AUTOSAR XML (schema 3.1.2)
package /Components/SWC_FISA
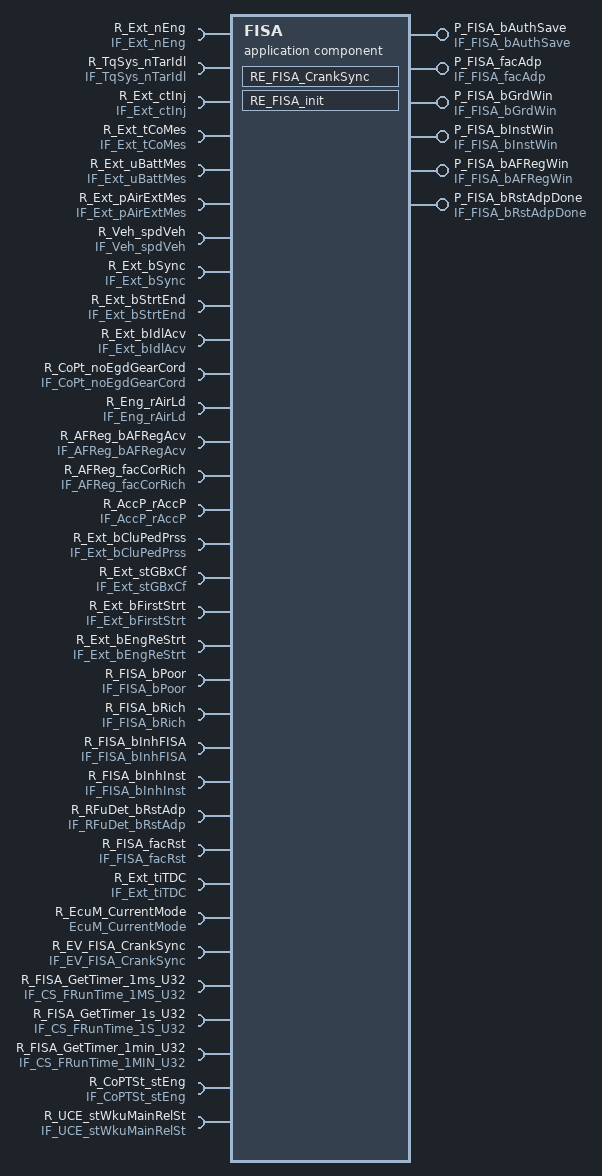
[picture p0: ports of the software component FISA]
  application software component type FISA
    6 x provide port:
      P_FISA_bAuthSave: unqueued-sender-com-spec{data-element=FISA_bAuthSave, can-invalidate=false, init-value=InitValue_Boolean_0}, provided-interface=IF_FISA_bAuthSave
      P_FISA_facAdp: unqueued-sender-com-spec{data-element=FISA_facAdp, can-invalidate=false, init-value=InitValue_UInt8_0}, provided-interface=IF_FISA_facAdp
      P_FISA_bGrdWin: unqueued-sender-com-spec{data-element=FISA_bGrdWin, can-invalidate=false, init-value=InitValue_Boolean_01}, provided-interface=IF_FISA_bGrdWin
      P_FISA_bInstWin: unqueued-sender-com-spec{data-element=FISA_bInstWin, can-invalidate=false, init-value=InitValue_Boolean_03}, provided-interface=IF_FISA_bInstWin
      P_FISA_bAFRegWin: unqueued-sender-com-spec{data-element=FISA_bAFRegWin, can-invalidate=false, init-value=InitValue_Boolean_05}, provided-interface=IF_FISA_bAFRegWin
      P_FISA_bRstAdpDone: unqueued-sender-com-spec{data-element=FISA_bRstAdpDone, can-invalidate=false, init-value=InitValue_Boolean_07}, provided-interface=IF_FISA_bRstAdpDone
    33 x require port:
      R_Ext_nEng: unqueued-receiver-com-spec{data-element=Ext_nEng, init-value=ConstantValue, resync-time=0}, required-interface=IF_Ext_nEng
      R_TqSys_nTarIdl: unqueued-receiver-com-spec{data-element=TqSys_nTarIdl, init-value=ConstantValue9, resync-time=0}, required-interface=IF_TqSys_nTarIdl
      R_Ext_ctInj: unqueued-receiver-com-spec{data-element=Ext_ctInj, init-value=InitValue_UInt16_0, resync-time=0}, required-interface=IF_Ext_ctInj
      R_Ext_tCoMes: unqueued-receiver-com-spec{data-element=Ext_tCoMes, init-value=ConstantValue11, resync-time=0}, required-interface=IF_Ext_tCoMes
      R_Ext_uBattMes: unqueued-receiver-com-spec{data-element=Ext_uBattMes, init-value=InitValue_SInt16_0, resync-time=0}, required-interface=IF_Ext_uBattMes
      R_Ext_pAirExtMes: unqueued-receiver-com-spec{data-element=Ext_pAirExtMes, init-value=ConstantValue13, resync-time=0}, required-interface=IF_Ext_pAirExtMes
      R_Veh_spdVeh: unqueued-receiver-com-spec{data-element=Veh_spdVeh, init-value=ConstantValue15, resync-time=0}, required-interface=IF_Veh_spdVeh
      R_Ext_bSync: unqueued-receiver-com-spec{data-element=Ext_bSync, init-value=InitValue_Boolean_017, resync-time=0}, required-interface=IF_Ext_bSync
      R_Ext_bStrtEnd: unqueued-receiver-com-spec{data-element=Ext_bStrtEnd, init-value=InitValue_Boolean_019, resync-time=0}, required-interface=IF_Ext_bStrtEnd
      R_Ext_bIdlAcv: unqueued-receiver-com-spec{data-element=Ext_bIdlAcv, init-value=InitValue_Boolean_021, resync-time=0}, required-interface=IF_Ext_bIdlAcv
      R_CoPt_noEgdGearCord: unqueued-receiver-com-spec{data-element=CoPt_noEgdGearCord, init-value=ConstantValue23, resync-time=0}, required-interface=IF_CoPt_noEgdGearCord
      R_Eng_rAirLd: unqueued-receiver-com-spec{data-element=Eng_rAirLd, init-value=InitValue_UInt16_025, resync-time=0}, required-interface=IF_Eng_rAirLd
      R_AFReg_bAFRegAcv: unqueued-receiver-com-spec{data-element=AFReg_bAFRegAcv, init-value=InitValue_Boolean_027, resync-time=0}, required-interface=IF_AFReg_bAFRegAcv
      R_AFReg_facCorRich: unqueued-receiver-com-spec{data-element=AFReg_facCorRich, init-value=InitValue_UInt16_029, resync-time=0}, required-interface=IF_AFReg_facCorRich
      R_AccP_rAccP: unqueued-receiver-com-spec{data-element=AccP_rAccP, init-value=ConstantValue31, resync-time=0}, required-interface=IF_AccP_rAccP
      R_Ext_bCluPedPrss: unqueued-receiver-com-spec{data-element=Ext_bCluPedPrss, init-value=ConstantValue33, resync-time=0}, required-interface=IF_Ext_bCluPedPrss
      R_Ext_stGBxCf: unqueued-receiver-com-spec{data-element=Ext_stGBxCf, init-value=ConstantValue35, resync-time=0}, required-interface=IF_Ext_stGBxCf
      R_Ext_bFirstStrt: unqueued-receiver-com-spec{data-element=Ext_bFirstStrt, init-value=InitValue_Boolean_037, resync-time=0}, required-interface=IF_Ext_bFirstStrt
      R_Ext_bEngReStrt: unqueued-receiver-com-spec{data-element=Ext_bEngReStrt, init-value=InitValue_Boolean_039, resync-time=0}, required-interface=IF_Ext_bEngReStrt
      R_FISA_bPoor: unqueued-receiver-com-spec{data-element=FISA_bPoor, init-value=InitValue_Boolean_041, resync-time=0}, required-interface=IF_FISA_bPoor
      R_FISA_bRich: unqueued-receiver-com-spec{data-element=FISA_bRich, init-value=InitValue_Boolean_043, resync-time=0}, required-interface=IF_FISA_bRich
      R_FISA_bInhFISA: unqueued-receiver-com-spec{data-element=FISA_bInhFISA, init-value=InitValue_Boolean_045, resync-time=0}, required-interface=IF_FISA_bInhFISA
      R_FISA_bInhInst: unqueued-receiver-com-spec{data-element=FISA_bInhInst, init-value=InitValue_Boolean_047, resync-time=0}, required-interface=IF_FISA_bInhInst
      R_RFuDet_bRstAdp: unqueued-receiver-com-spec{data-element=RFuDet_bRstAdp, init-value=InitValue_Boolean_049, resync-time=0}, required-interface=IF_RFuDet_bRstAdp
      R_FISA_facRst: unqueued-receiver-com-spec{data-element=FISA_facRst, init-value=InitValue_UInt8_051, resync-time=0}, required-interface=IF_FISA_facRst
      R_Ext_tiTDC: unqueued-receiver-com-spec{data-element=Ext_tiTDC, init-value=ConstantValue53, resync-time=0}, required-interface=IF_Ext_tiTDC
      R_EcuM_CurrentMode: required-interface=EcuM_CurrentMode
      R_EV_FISA_CrankSync: unqueued-receiver-com-spec{data-element=EV_FISA_CrankSync, init-value=InitValue_UInt8_055, resync-time=0}, required-interface=IF_EV_FISA_CrankSync
      R_FISA_GetTimer_1ms_U32: required-interface=IF_CS_FRunTime_1MS_U32
      R_FISA_GetTimer_1s_U32: required-interface=IF_CS_FRunTime_1S_U32
      R_FISA_GetTimer_1min_U32: required-interface=IF_CS_FRunTime_1MIN_U32
      R_CoPTSt_stEng: unqueued-receiver-com-spec{data-element=CoPTSt_stEng, init-value=ConstantValue57, resync-time=0}, required-interface=IF_CoPTSt_stEng
      R_UCE_stWkuMainRelSt: required-interface=IF_UCE_stWkuMainRelSt
  45 x constant specification:
    ConstantValue
      value:
        integer literal ConstantValue: type=DT_Ext_nEng, value=0
    ConstantValue11
      value:
        integer literal ConstantValue11: type=DT_Ext_tCoMes, value=20
    ConstantValue13
      value:
        integer literal ConstantValue13: type=DT_Ext_pAirExtMes, value=500
    ConstantValue15
      value:
        integer literal ConstantValue15: type=DT_Veh_spdVeh, value=0
    ConstantValue23
      value:
        integer literal ConstantValue23: type=DT_CoPt_noEgdGearCord, value=0
    ConstantValue31
      value:
        integer literal ConstantValue31: type=DT_AccP_rAccP, value=0
    ConstantValue33
      value:
        boolean literal ConstantValue33: type=DT_Ext_bCluPedPrss, value=false
    ConstantValue35
      value:
        integer literal ConstantValue35: type=DT_Ext_stGBxCf, value=0
    ConstantValue53
      value:
        integer literal ConstantValue53: type=DT_Ext_tiTDC, value=100
    ConstantValue57
      value:
        integer literal ConstantValue57: type=DT_CoPTSt_stEng, value=1
    ConstantValue9
      value:
        integer literal ConstantValue9: type=DT_TqSys_nTarIdl, value=0
    InitValue_Boolean_0
      value:
        boolean literal InitValue_Boolean_0: type=DT_FISA_bAuthSave, value=false
    InitValue_Boolean_01
      value:
        boolean literal InitValue_Boolean_01: type=DT_FISA_bGrdWin, value=false
    InitValue_Boolean_017
      value:
        boolean literal InitValue_Boolean_017: type=DT_Ext_bSync, value=false
    InitValue_Boolean_019
      value:
        boolean literal InitValue_Boolean_019: type=DT_Ext_bStrtEnd, value=false
    InitValue_Boolean_021
      value:
        boolean literal InitValue_Boolean_021: type=DT_Ext_bIdlAcv, value=false
    InitValue_Boolean_027
      value:
        boolean literal InitValue_Boolean_027: type=DT_AFReg_bAFRegAcv, value=false
    InitValue_Boolean_03
      value:
        boolean literal InitValue_Boolean_03: type=DT_FISA_bInstWin, value=false
    InitValue_Boolean_037
      value:
        boolean literal InitValue_Boolean_037: type=DT_Ext_bFirstStrt, value=false
    InitValue_Boolean_039
      value:
        boolean literal InitValue_Boolean_039: type=DT_Ext_bEngReStrt, value=false
    InitValue_Boolean_041
      value:
        boolean literal InitValue_Boolean_041: type=DT_FISA_bPoor, value=false
    InitValue_Boolean_043
      value:
        boolean literal InitValue_Boolean_043: type=DT_FISA_bRich, value=false
    InitValue_Boolean_045
      value:
        boolean literal InitValue_Boolean_045: type=DT_FISA_bInhFISA, value=false
    InitValue_Boolean_047
      value:
        boolean literal InitValue_Boolean_047: type=DT_FISA_bInhInst, value=false
    InitValue_Boolean_049
      value:
        boolean literal InitValue_Boolean_049: type=DT_RFuDet_bRstAdp, value=false
    InitValue_Boolean_05
      value:
        boolean literal InitValue_Boolean_05: type=DT_FISA_bAFRegWin, value=false
    InitValue_Boolean_061
      value:
        boolean literal InitValue_Boolean_061: type=DT_bAFRegWin, value=false
    InitValue_Boolean_065
      value:
        boolean literal InitValue_Boolean_065: type=DT_bAuthClc, value=false
    InitValue_Boolean_069
      value:
        boolean literal InitValue_Boolean_069: type=DT_bInstWin, value=false
    InitValue_Boolean_07
      value:
        boolean literal InitValue_Boolean_07: type=DT_FISA_bRstAdpDone, value=false
    InitValue_Boolean_071
      value:
        boolean literal InitValue_Boolean_071: type=DT_bGrdWin, value=false
    InitValue_SInt16_0
      value:
        integer literal InitValue_SInt16_0: type=DT_Ext_uBattMes, value=1200
    InitValue_SInt8_0
      value:
        integer literal InitValue_SInt8_0: type=DT_facDifAst, value=0
    InitValue_SInt8_063
      value:
        integer literal InitValue_SInt8_063: type=DT_facDifStrt, value=0
    InitValue_SInt8_073
      value:
        integer literal InitValue_SInt8_073: type=DT_facDifAFReg, value=0
    InitValue_UInt16_0
      value:
        integer literal InitValue_UInt16_0: type=DT_Ext_ctInj, value=0
    InitValue_UInt16_025
      value:
        integer literal InitValue_UInt16_025: type=DT_Eng_rAirLd, value=0
    InitValue_UInt16_029
      value:
        integer literal InitValue_UInt16_029: type=DT_AFReg_facCorRich, value=0
    InitValue_UInt16_077
      value:
        integer literal InitValue_UInt16_077: type=DT_uMinGdStrt, value=0
    InitValue_UInt8_0
      value:
        integer literal InitValue_UInt8_0: type=DT_FISA_facAdp, value=0
    InitValue_UInt8_051
      value:
        integer literal InitValue_UInt8_051: type=DT_FISA_facRst, value=0
    InitValue_UInt8_055
      value:
        integer literal InitValue_UInt8_055: type=DT_EV_FISA_CrankSync, value=0
    InitValue_UInt8_059
      value:
        integer literal InitValue_UInt8_059: type=DT_noInjStopAdp, value=0
    InitValue_UInt8_067
      value:
        integer literal InitValue_UInt8_067: type=DT_idxTypIni, value=0
    InitValue_UInt8_075
      value:
        integer literal InitValue_UInt8_075: type=DT_idxTypFac, value=0
  internal behavior IB_FISA: component=FISA
    mode switch event EV_FISA_Init: start-on-event=RE_FISA_init, activation=ENTRY, mode=R_EcuM_CurrentMode.currentMode.RUN
    data received event EV_FISA_CrankSync: mode-dependency=dependent-on-mode=[R_UCE_stWkuMainRelSt.RCD_stWkuMainRelSt.PreMainWakeUp, R_UCE_stWkuMainRelSt.RCD_stWkuMainRelSt.PostMainWakeUp, R_UCE_stWkuMainRelSt.RCD_stWkuMainRelSt.Invalid], start-on-event=RE_FISA_CrankSync, data=R_EV_FISA_CrankSync.EV_FISA_CrankSync
    11 x inter runnable variable, all with sw-calibration-access=READ-WRITE, communication-approach=EXPLICIT:
      bInstWin: type=DT_bInstWin, init-value=InitValue_Boolean_069
      facDifAst: type=DT_facDifAst, init-value=InitValue_SInt8_0
      noInjStopAdp: type=DT_noInjStopAdp, init-value=InitValue_UInt8_059
      idxTypFac: type=DT_idxTypFac, init-value=InitValue_UInt8_075
      facDifAFReg: type=DT_facDifAFReg, init-value=InitValue_SInt8_073
      bAuthClc: type=DT_bAuthClc, init-value=InitValue_Boolean_065
      uMinGdStrt: type=DT_uMinGdStrt, init-value=InitValue_UInt16_077
      facDifStrt: type=DT_facDifStrt, init-value=InitValue_SInt8_063
      bAFRegWin: type=DT_bAFRegWin, init-value=InitValue_Boolean_061
      idxTypIni: type=DT_idxTypIni, init-value=InitValue_UInt8_067
      bGrdWin: type=DT_bGrdWin, init-value=InitValue_Boolean_071
    runnable RE_FISA_CrankSync: read-variable=[facDifAFReg, bInstWin, bAFRegWin, facDifStrt, idxTypFac, idxTypIni, bGrdWin, uMinGdStrt, noInjStopAdp, facDifAst, bAuthClc], written-variable=[facDifAFReg, bInstWin, bAFRegWin, facDifStrt, idxTypFac, idxTypIni, bGrdWin, uMinGdStrt, noInjStopAdp, facDifAst, bAuthClc]
      28 x data receive point:
        dr_AccP_rAccP: data-element=R_AccP_rAccP.AccP_rAccP
        dr_CoPt_noEgdGearCord: data-element=R_CoPt_noEgdGearCord.CoPt_noEgdGearCord
        dr_FISA_bRich: data-element=R_FISA_bRich.FISA_bRich
        dr_FISA_facRst: data-element=R_FISA_facRst.FISA_facRst
        dr_Ext_ctInj: data-element=R_Ext_ctInj.Ext_ctInj
        dr_Ext_nEng: data-element=R_Ext_nEng.Ext_nEng
        dr_Ext_pAirExtMes: data-element=R_Ext_pAirExtMes.Ext_pAirExtMes
        dr_FISA_bInhFISA: data-element=R_FISA_bInhFISA.FISA_bInhFISA
        dr_EV_FISA_CrankSync: data-element=R_EV_FISA_CrankSync.EV_FISA_CrankSync
        dr_Ext_stGBxCf: data-element=R_Ext_stGBxCf.Ext_stGBxCf
        dr_FISA_bPoor: data-element=R_FISA_bPoor.FISA_bPoor
        dr_RFuDet_bRstAdp: data-element=R_RFuDet_bRstAdp.RFuDet_bRstAdp
        dr_AFReg_bAFRegAcv: data-element=R_AFReg_bAFRegAcv.AFReg_bAFRegAcv
        dr_Ext_tCoMes: data-element=R_Ext_tCoMes.Ext_tCoMes
        dr_Ext_uBattMes: data-element=R_Ext_uBattMes.Ext_uBattMes
        dr_CoPTSt_stEng: data-element=R_CoPTSt_stEng.CoPTSt_stEng
        dr_Ext_bSync: data-element=R_Ext_bSync.Ext_bSync
        dr_Ext_bIdlAcv: data-element=R_Ext_bIdlAcv.Ext_bIdlAcv
        dr_AFReg_facCorRich: data-element=R_AFReg_facCorRich.AFReg_facCorRich
        dr_Eng_rAirLd: data-element=R_Eng_rAirLd.Eng_rAirLd
        dr_Ext_bFirstStrt: data-element=R_Ext_bFirstStrt.Ext_bFirstStrt
        dr_TqSys_nTarIdl: data-element=R_TqSys_nTarIdl.TqSys_nTarIdl
        dr_Ext_bEngReStrt: data-element=R_Ext_bEngReStrt.Ext_bEngReStrt
        dr_Ext_tiTDC: data-element=R_Ext_tiTDC.Ext_tiTDC
        dr_Veh_spdVeh: data-element=R_Veh_spdVeh.Veh_spdVeh
        dr_Ext_bStrtEnd: data-element=R_Ext_bStrtEnd.Ext_bStrtEnd
        dr_Ext_bCluPedPrss: data-element=R_Ext_bCluPedPrss.Ext_bCluPedPrss
        dr_FISA_bInhInst: data-element=R_FISA_bInhInst.FISA_bInhInst
      6 x data send point:
        ds_FISA_facAdp: data-element=P_FISA_facAdp.FISA_facAdp
        ds_FISA_bAuthSave: data-element=P_FISA_bAuthSave.FISA_bAuthSave
        ds_FISA_bGrdWin: data-element=P_FISA_bGrdWin.FISA_bGrdWin
        ds_FISA_bRstAdpDone: data-element=P_FISA_bRstAdpDone.FISA_bRstAdpDone
        ds_FISA_bAFRegWin: data-element=P_FISA_bAFRegWin.FISA_bAFRegWin
        ds_FISA_bInstWin: data-element=P_FISA_bInstWin.FISA_bInstWin
      sync call ssp_GetTimer_1min_U32: operation=R_FISA_GetTimer_1min_U32.GetTimer_1min_U32
      sync call ssp_GetTimer_1ms_U32: operation=R_FISA_GetTimer_1ms_U32.GetTimer_1ms_U32
      sync call ssp_GetTimer_1s_U32: operation=R_FISA_GetTimer_1s_U32.GetTimer_1s_U32
    runnable RE_FISA_init: written-variable=[bAFRegWin, noInjStopAdp, bAuthClc, bGrdWin, idxTypFac, bInstWin, idxTypIni, facDifStrt, uMinGdStrt, facDifAst, facDifAFReg]
      26 x data receive point:
        dr_Ext_bCluPedPrss: data-element=R_Ext_bCluPedPrss.Ext_bCluPedPrss
        dr_Ext_nEng: data-element=R_Ext_nEng.Ext_nEng
        dr_Ext_bEngReStrt: data-element=R_Ext_bEngReStrt.Ext_bEngReStrt
        dr_FISA_facRst: data-element=R_FISA_facRst.FISA_facRst
        dr_AFReg_bAFRegAcv: data-element=R_AFReg_bAFRegAcv.AFReg_bAFRegAcv
        dr_Ext_bFirstStrt: data-element=R_Ext_bFirstStrt.Ext_bFirstStrt
        dr_Ext_tCoMes: data-element=R_Ext_tCoMes.Ext_tCoMes
        dr_Veh_spdVeh: data-element=R_Veh_spdVeh.Veh_spdVeh
        dr_AccP_rAccP: data-element=R_AccP_rAccP.AccP_rAccP
        dr_Ext_ctInj: data-element=R_Ext_ctInj.Ext_ctInj
        dr_RFuDet_bRstAdp: data-element=R_RFuDet_bRstAdp.RFuDet_bRstAdp
        dr_Ext_bIdlAcv: data-element=R_Ext_bIdlAcv.Ext_bIdlAcv
        dr_Ext_pAirExtMes: data-element=R_Ext_pAirExtMes.Ext_pAirExtMes
        dr_Eng_rAirLd: data-element=R_Eng_rAirLd.Eng_rAirLd
        dr_Ext_stGBxCf: data-element=R_Ext_stGBxCf.Ext_stGBxCf
        dr_FISA_bInhFISA: data-element=R_FISA_bInhFISA.FISA_bInhFISA
        dr_Ext_bSync: data-element=R_Ext_bSync.Ext_bSync
        dr_FISA_bInhInst: data-element=R_FISA_bInhInst.FISA_bInhInst
        dr_CoPt_noEgdGearCord: data-element=R_CoPt_noEgdGearCord.CoPt_noEgdGearCord
        dr_Ext_bStrtEnd: data-element=R_Ext_bStrtEnd.Ext_bStrtEnd
        dr_Ext_uBattMes: data-element=R_Ext_uBattMes.Ext_uBattMes
        dr_TqSys_nTarIdl: data-element=R_TqSys_nTarIdl.TqSys_nTarIdl
        dr_Ext_tiTDC: data-element=R_Ext_tiTDC.Ext_tiTDC
        dr_FISA_bPoor: data-element=R_FISA_bPoor.FISA_bPoor
        dr_FISA_bRich: data-element=R_FISA_bRich.FISA_bRich
        dr_AFReg_facCorRich: data-element=R_AFReg_facCorRich.AFReg_facCorRich
      6 x data send point:
        ds_FISA_bInstWin: data-element=P_FISA_bInstWin.FISA_bInstWin
        ds_FISA_bGrdWin: data-element=P_FISA_bGrdWin.FISA_bGrdWin
        ds_FISA_bRstAdpDone: data-element=P_FISA_bRstAdpDone.FISA_bRstAdpDone
        ds_FISA_bAuthSave: data-element=P_FISA_bAuthSave.FISA_bAuthSave
        ds_FISA_facAdp: data-element=P_FISA_facAdp.FISA_facAdp
        ds_FISA_bAFRegWin: data-element=P_FISA_bAFRegWin.FISA_bAFRegWin
  swc implementation Imp_FISA: programming-language=C, behavior=IB_FISA
    code-descriptors:
      code CodeDescriptor: type=SRC
        21 x xfile:
          FISA_Runnables_h: url=FISA_Runnables.h
          FISA_fixed_h: url=FISA_fixed.h
          FISA_Calibration_h: url=FISA_Calibration.h
          FISA_MemMap_h: url=FISA_MemMap.h
          FISA_SupervFctAdaptInj_h: url=FISA_SupervFctAdaptInj.h
          FISA_Version_h: url=FISA_Version.h
          FISA_nvm_c: url=FISA_nvm.c
          FISA_DetermVal_c: url=FISA_DetermVal.c
          FISA_Runnables_c: url=FISA_Runnables.c
          FISA_ApprentiQltCarb_c: url=FISA_ApprentiQltCarb.c
          FISA_Version_c: url=FISA_Version.c
          FISA_SupervFctAdaptInj_c: url=FISA_SupervFctAdaptInj.c
          FISA_ApprentiQltCarb_h: url=FISA_ApprentiQltCarb.h
          FISA_lib_h: url=FISA_lib.h
          FISA_lib_c: url=FISA_lib.c
          FISA_nvm_h: url=FISA_nvm.h
          FISA_ConfirmationApDem_c: url=FISA_ConfirmationApDem.c
          FISA_ConfirmationApDem_h: url=FISA_ConfirmationApDem.h
          FISA_DetermVal_h: url=FISA_DetermVal.h
          FISA_fixed_c: url=FISA_fixed.c
          FISA_Calibration_c: url=FISA_Calibration.c
package /Components/SWC_FISA/FISA_IRVDatatypes
  4 x boolean type, all with base-type=boolean:
    DT_bAFRegWin
    DT_bAuthClc
    DT_bGrdWin
    DT_bInstWin
  7 x integer type:
    DT_facDifAFReg: base-type=int8, lower-limit=-128, upper-limit=127
    DT_facDifAst: base-type=int8, lower-limit=-128, upper-limit=127
    DT_facDifStrt: base-type=int8, lower-limit=-128, upper-limit=127
    DT_idxTypFac: base-type=uint8, lower-limit=0, upper-limit=255
    DT_idxTypIni: base-type=uint8, lower-limit=0, upper-limit=255
    DT_noInjStopAdp: base-type=uint8, lower-limit=0, upper-limit=255
    DT_uMinGdStrt: base-type=uint16, lower-limit=0, upper-limit=65535
